AUTOSAR XML (schema 00044)
package /ComponentTypes
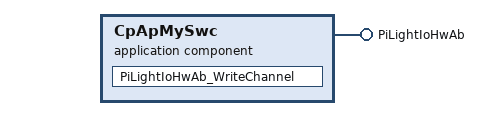
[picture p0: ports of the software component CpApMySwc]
  application sw component type CpApMySwc
    provide port PiLightIoHwAb: server-com-spec{operation=WriteChannel, queue-length=1}, provided-interface=PiLightIoHwAb
    behavior CpApMySwc_InternalBehavior
      operation invoked event OIT_PiLightIoHwAb_WriteChannel_PiLightIoHwAb_WriteChannel: start-on-event=PiLightIoHwAb_WriteChannel, operation=PiLightIoHwAb.WriteChannel
      runnable PiLightIoHwAb_WriteChannel
  swc implementation CpApMySwc_Implementation: behavior=CpApMySwc_InternalBehavior
